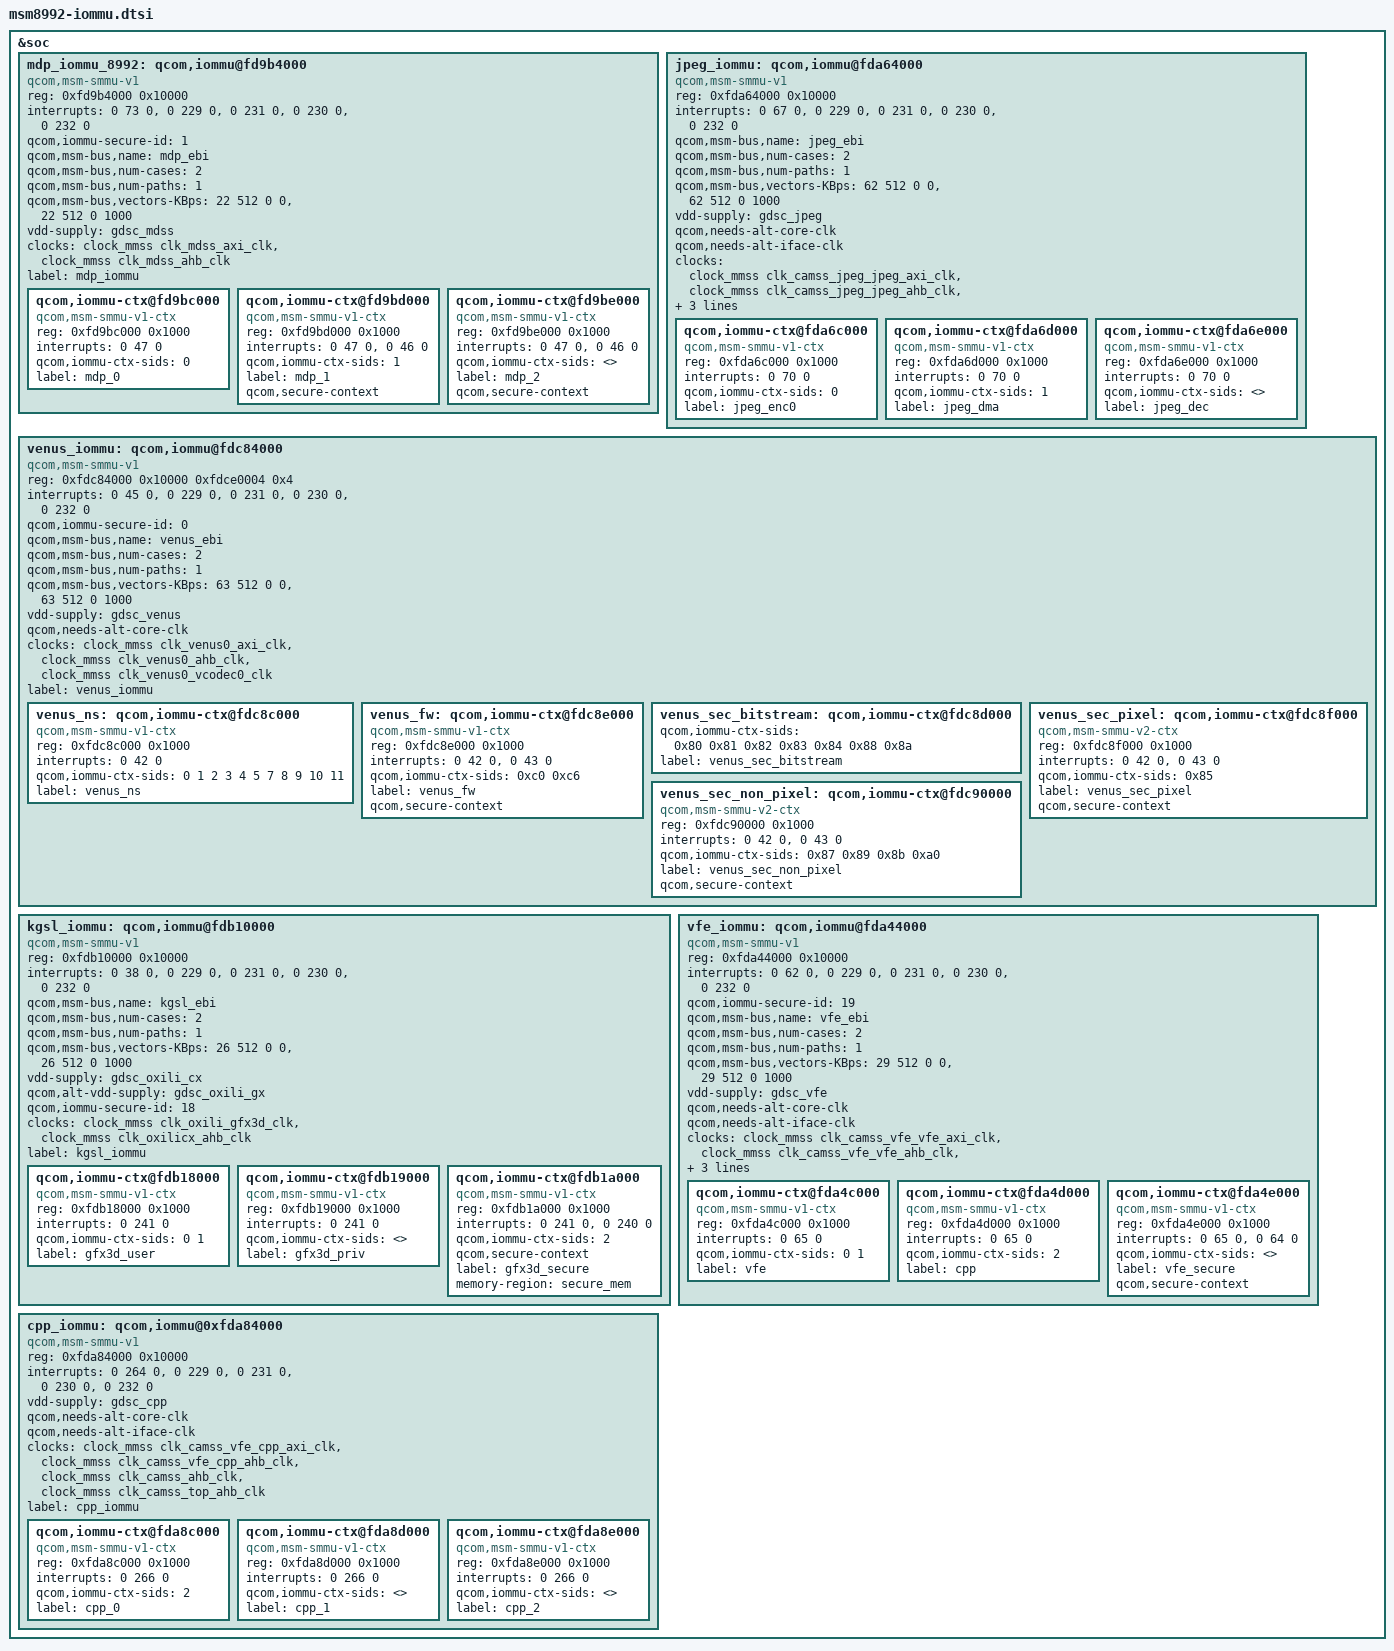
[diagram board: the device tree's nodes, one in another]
/* Copyright (c) 2012-2014, The Linux Foundation. All rights reserved.
 *
 * This program is free software; you can redistribute it and/or modify
 * it under the terms of the GNU General Public License version 2 and
 * only version 2 as published by the Free Software Foundation.
 *
 * This program is distributed in the hope that it will be useful,
 * but WITHOUT ANY WARRANTY; without even the implied warranty of
 * MERCHANTABILITY or FITNESS FOR A PARTICULAR PURPOSE.  See the
 * GNU General Public License for more details.
 */

&soc {
	mdp_iommu_8992: qcom,iommu@fd9b4000 {
		compatible = "qcom,msm-smmu-v1";
		#address-cells = <1>;
		#size-cells = <1>;
		#iommu-cells = <1>;
		ranges;
		reg = <0xfd9b4000 0x10000>;
		reg-names = "iommu_base";
		interrupts = <0 73 0>,
				<0 229 0>, <0 231 0>,
				<0 230 0>, <0 232 0>;
		interrupt-names = "pmon",
				"global_cfg_NS_irq", "global_client_NS_irq",
				"global_cfg_S_irq", "global_client_S_irq";
		qcom,iommu-secure-id = <1>;

		qcom,msm-bus,name = "mdp_ebi";
		qcom,msm-bus,num-cases = <2>;
		qcom,msm-bus,num-paths = <1>;
		qcom,msm-bus,vectors-KBps =
				<22 512 0 0>,
				<22 512 0 1000>;

		vdd-supply = <&gdsc_mdss>;
		clocks = <&clock_mmss clk_mdss_axi_clk>,
			<&clock_mmss clk_mdss_ahb_clk>;
		clock-names = "core_clk", "iface_clk";
		label = "mdp_iommu";
		status = "ok";

		qcom,iommu-ctx@fd9bc000 {
			compatible = "qcom,msm-smmu-v1-ctx";
			reg = <0xfd9bc000 0x1000>;
			interrupts = <0 47 0>;
			qcom,iommu-ctx-sids = <0>;
			label = "mdp_0";
		};

		qcom,iommu-ctx@fd9bd000 {
			compatible = "qcom,msm-smmu-v1-ctx";
			reg = <0xfd9bd000 0x1000>;
			interrupts = <0 47 0>, <0 46 0>;
			qcom,iommu-ctx-sids = <1>;
			label = "mdp_1";
			qcom,secure-context;
		};

		qcom,iommu-ctx@fd9be000 {
			compatible = "qcom,msm-smmu-v1-ctx";
			reg = <0xfd9be000 0x1000>;
			interrupts = <0 47 0>, <0 46 0>;
			qcom,iommu-ctx-sids = <>;
			label = "mdp_2";
			qcom,secure-context;
		};
	};

	jpeg_iommu: qcom,iommu@fda64000 {
		compatible = "qcom,msm-smmu-v1";
		#address-cells = <1>;
		#size-cells = <1>;
		#iommu-cells = <1>;
		ranges;
		reg = <0xfda64000 0x10000>;
		reg-names = "iommu_base";
		interrupts = <0 67 0>,
				<0 229 0>, <0 231 0>,
				<0 230 0>, <0 232 0>;
		interrupt-names = "pmon",
				"global_cfg_NS_irq", "global_client_NS_irq",
				"global_cfg_S_irq", "global_client_S_irq";

		qcom,msm-bus,name = "jpeg_ebi";
		qcom,msm-bus,num-cases = <2>;
		qcom,msm-bus,num-paths = <1>;
		qcom,msm-bus,vectors-KBps =
				<62 512 0 0>,
				<62 512 0 1000>;

		vdd-supply = <&gdsc_jpeg>;
		qcom,needs-alt-core-clk;
		qcom,needs-alt-iface-clk;
		clocks = <&clock_mmss clk_camss_jpeg_jpeg_axi_clk>,
			<&clock_mmss clk_camss_jpeg_jpeg_ahb_clk>,
			<&clock_mmss clk_camss_ahb_clk>,
			<&clock_mmss clk_camss_top_ahb_clk>;
		clock-names = "core_clk", "iface_clk", "alt_iface_clk", "alt_core_clk";
		label = "jpeg_iommu";
		status = "ok";

		qcom,iommu-ctx@fda6c000 {
			compatible = "qcom,msm-smmu-v1-ctx";
			reg = <0xfda6c000 0x1000>;
			interrupts = <0 70 0>;
			qcom,iommu-ctx-sids = <0>;
			label = "jpeg_enc0";
		};

		qcom,iommu-ctx@fda6d000 {
			compatible = "qcom,msm-smmu-v1-ctx";
			reg = <0xfda6d000 0x1000>;
			interrupts = <0 70 0>;
			qcom,iommu-ctx-sids = <1>;
			label = "jpeg_dma";
		};

		qcom,iommu-ctx@fda6e000 {
			compatible = "qcom,msm-smmu-v1-ctx";
			reg = <0xfda6e000 0x1000>;
			interrupts = <0 70 0>;
			qcom,iommu-ctx-sids = <>;
			label = "jpeg_dec";
		};
	};

	venus_iommu: qcom,iommu@fdc84000 {
		compatible = "qcom,msm-smmu-v1";
		#address-cells = <1>;
		#size-cells = <1>;
		#iommu-cells = <1>;
		ranges;
		reg = <0xfdc84000 0x10000
		       0xfdce0004 0x4>;
		reg-names = "iommu_base", "clk_base";
		interrupts = <0 45 0>,
				<0 229 0>, <0 231 0>,
				<0 230 0>, <0 232 0>;
		interrupt-names = "pmon",
				"global_cfg_NS_irq", "global_client_NS_irq",
				"global_cfg_S_irq", "global_client_S_irq";
		qcom,iommu-secure-id = <0>;

		qcom,msm-bus,name = "venus_ebi";
		qcom,msm-bus,num-cases = <2>;
		qcom,msm-bus,num-paths = <1>;
		qcom,msm-bus,vectors-KBps =
				<63 512 0 0>,
				<63 512 0 1000>;

		vdd-supply = <&gdsc_venus>;
		qcom,needs-alt-core-clk;
		clocks = <&clock_mmss clk_venus0_axi_clk>,
			<&clock_mmss clk_venus0_ahb_clk>,
			<&clock_mmss clk_venus0_vcodec0_clk>;
		clock-names = "core_clk", "iface_clk", "alt_core_clk";
		label = "venus_iommu";
		status = "ok";

		venus_ns: qcom,iommu-ctx@fdc8c000 {
			compatible = "qcom,msm-smmu-v1-ctx";
			reg = <0xfdc8c000 0x1000>;
			interrupts = <0 42 0>;
			qcom,iommu-ctx-sids = <0 1 2 3 4 5 7 8 9 10 11>;
			label = "venus_ns";
		};

		venus_fw: qcom,iommu-ctx@fdc8e000 {
			compatible = "qcom,msm-smmu-v1-ctx";
			reg = <0xfdc8e000 0x1000>;
			interrupts = <0 42 0>, <0 43 0>;
			qcom,iommu-ctx-sids = <0xc0 0xc6>;
			label = "venus_fw";
			qcom,secure-context;
		};
		////////msm8992
		venus_sec_bitstream: qcom,iommu-ctx@fdc8d000 {
			qcom,iommu-ctx-sids = <0x80 0x81 0x82 0x83 0x84 0x88 0x8a>;
			label = "venus_sec_bitstream";
		};

		venus_sec_pixel: qcom,iommu-ctx@fdc8f000 {
			compatible = "qcom,msm-smmu-v2-ctx";
			reg = <0xfdc8f000 0x1000>;
			interrupts = <0 42 0>, <0 43 0>;
			qcom,iommu-ctx-sids = <0x85>;
			label = "venus_sec_pixel";
			qcom,secure-context;
		};

		venus_sec_non_pixel: qcom,iommu-ctx@fdc90000 {
			compatible = "qcom,msm-smmu-v2-ctx";
			reg = <0xfdc90000 0x1000>;
			interrupts = <0 42 0>, <0 43 0>;
			qcom,iommu-ctx-sids = <0x87 0x89 0x8b 0xa0>;
			label = "venus_sec_non_pixel";
			qcom,secure-context;
		};
	};

	kgsl_iommu: qcom,iommu@fdb10000 {
		compatible = "qcom,msm-smmu-v1";
		#address-cells = <1>;
		#size-cells = <1>;
		#iommu-cells = <1>;
		ranges;
		reg = <0xfdb10000 0x10000>;
		reg-names = "iommu_base";
		interrupts = <0 38 0>,
				<0 229 0>, <0 231 0>,
				<0 230 0>, <0 232 0>;
		interrupt-names = "pmon",
				"global_cfg_NS_irq", "global_client_NS_irq",
				"global_cfg_S_irq", "global_client_S_irq";

		qcom,msm-bus,name = "kgsl_ebi";
		qcom,msm-bus,num-cases = <2>;
		qcom,msm-bus,num-paths = <1>;
		qcom,msm-bus,vectors-KBps =
				<26 512 0 0>,
				<26 512 0 1000>;

		vdd-supply = <&gdsc_oxili_cx>;
		qcom,alt-vdd-supply = <&gdsc_oxili_gx>;
		qcom,iommu-secure-id = <18>;
		clocks = <&clock_mmss clk_oxili_gfx3d_clk>,
			<&clock_mmss clk_oxilicx_ahb_clk>;
		clock-names = "core_clk", "iface_clk";
		label = "kgsl_iommu";
		status = "ok";

		qcom,iommu-ctx@fdb18000 {
			compatible = "qcom,msm-smmu-v1-ctx";
			reg = <0xfdb18000 0x1000>;
			interrupts = <0 241 0>;
			qcom,iommu-ctx-sids = <0 1>;
			label = "gfx3d_user";
		};

		qcom,iommu-ctx@fdb19000 {
			compatible = "qcom,msm-smmu-v1-ctx";
			reg = <0xfdb19000 0x1000>;
			interrupts = <0 241 0>;
			qcom,iommu-ctx-sids = <>;
			label = "gfx3d_priv";
		};

		qcom,iommu-ctx@fdb1a000 {
			compatible = "qcom,msm-smmu-v1-ctx";
			reg = <0xfdb1a000 0x1000>;
			interrupts = <0 241 0>, <0 240 0>;
			qcom,iommu-ctx-sids = <2>;
			qcom,secure-context;
			label = "gfx3d_secure";
			memory-region = <&secure_mem>;
		};

	};

	vfe_iommu: qcom,iommu@fda44000 {
		compatible = "qcom,msm-smmu-v1";
		#address-cells = <1>;
		#size-cells = <1>;
		#iommu-cells = <1>;
		ranges;
		reg = <0xfda44000 0x10000>;
		reg-names = "iommu_base";
		interrupts = <0 62 0>,
				<0 229 0>, <0 231 0>,
				<0 230 0>, <0 232 0>;
		interrupt-names = "pmon",
				"global_cfg_NS_irq", "global_client_NS_irq",
				"global_cfg_S_irq", "global_client_S_irq";

		qcom,iommu-secure-id = <19>;
		qcom,msm-bus,name = "vfe_ebi";
		qcom,msm-bus,num-cases = <2>;
		qcom,msm-bus,num-paths = <1>;
		qcom,msm-bus,vectors-KBps =
				<29 512 0 0>,
				<29 512 0 1000>;

		vdd-supply = <&gdsc_vfe>;
		qcom,needs-alt-core-clk;
		qcom,needs-alt-iface-clk;
		clocks = <&clock_mmss clk_camss_vfe_vfe_axi_clk>,
			<&clock_mmss clk_camss_vfe_vfe_ahb_clk>,
			<&clock_mmss clk_camss_ahb_clk>,
			<&clock_mmss clk_camss_top_ahb_clk>;
		clock-names = "core_clk", "iface_clk", "alt_iface_clk", "alt_core_clk";
		label = "vfe_iommu";
		status = "ok";

		qcom,iommu-ctx@fda4c000 {
			compatible = "qcom,msm-smmu-v1-ctx";
			reg = <0xfda4c000 0x1000>;
			interrupts = <0 65 0>;
			qcom,iommu-ctx-sids = <0 1>;
			label = "vfe";
		};

		qcom,iommu-ctx@fda4d000 {
			compatible = "qcom,msm-smmu-v1-ctx";
			reg = <0xfda4d000 0x1000>;
			interrupts = <0 65 0>;
			qcom,iommu-ctx-sids = <2>;
			label = "cpp";
		};

		qcom,iommu-ctx@fda4e000 {
			compatible = "qcom,msm-smmu-v1-ctx";
			reg = <0xfda4e000 0x1000>;
			interrupts = <0 65 0>, <0 64 0>;
			qcom,iommu-ctx-sids = <>;
			label = "vfe_secure";
			qcom,secure-context;
		};
	};

	cpp_iommu: qcom,iommu@0xfda84000 {
		compatible = "qcom,msm-smmu-v1";
		#address-cells = <1>;
		#size-cells = <1>;
		#iommu-cells = <1>;
		ranges;
		reg = <0xfda84000 0x10000>;
		reg-names = "iommu_base";
		interrupts = <0 264 0>,
				<0 229 0>, <0 231 0>,
				<0 230 0>, <0 232 0>;
		interrupt-names = "pmon",
				"global_cfg_NS_irq", "global_client_NS_irq",
				"global_cfg_S_irq", "global_client_S_irq";

		vdd-supply = <&gdsc_cpp>;
		qcom,needs-alt-core-clk;
		qcom,needs-alt-iface-clk;
		clocks = <&clock_mmss clk_camss_vfe_cpp_axi_clk>,
			<&clock_mmss clk_camss_vfe_cpp_ahb_clk>,
			<&clock_mmss clk_camss_ahb_clk>,
			<&clock_mmss clk_camss_top_ahb_clk>;
		clock-names = "core_clk", "iface_clk", "alt_iface_clk", "alt_core_clk";
		label = "cpp_iommu";
		status = "ok";

		qcom,iommu-ctx@fda8c000 {
			compatible = "qcom,msm-smmu-v1-ctx";
			reg = <0xfda8c000 0x1000>;
			interrupts = <0 266 0>;
			qcom,iommu-ctx-sids = <2>;
			label = "cpp_0";
		};

		qcom,iommu-ctx@fda8d000 {
			compatible = "qcom,msm-smmu-v1-ctx";
			reg = <0xfda8d000 0x1000>;
			interrupts = <0 266 0>;
			qcom,iommu-ctx-sids = <>;
			label = "cpp_1";
		};

		qcom,iommu-ctx@fda8e000 {
			compatible = "qcom,msm-smmu-v1-ctx";
			reg = <0xfda8e000 0x1000>;
			interrupts = <0 266 0>;
			qcom,iommu-ctx-sids = <>;
			label = "cpp_2";
		};
	};

};
